AUTOSAR XML (schema 4-3-0)
package /test_pkg/test_swc
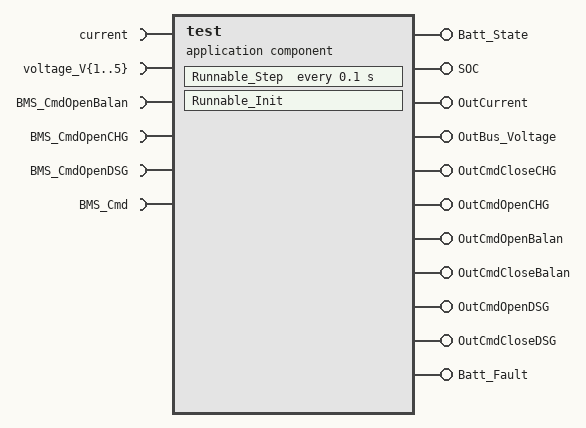
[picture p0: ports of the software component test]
  application sw component type test
    10 x require port:
      current: nonqueued-receiver-com-spec{data-element=current, init-value=0}, required-interface=current
      voltage_V{1..5}: nonqueued-receiver-com-spec{data-element=voltage_V{1..5}, init-value=0}, required-interface=voltage_V{1..5}
      BMS_CmdOpenBalan: nonqueued-receiver-com-spec{data-element=BMS_CmdOpenBalan, init-value=0}, required-interface=BMS_CmdOpenBalan
      BMS_CmdOpenCHG: nonqueued-receiver-com-spec{data-element=BMS_CmdOpenCHG, init-value=0}, required-interface=BMS_CmdOpenCHG
      BMS_CmdOpenDSG: nonqueued-receiver-com-spec{data-element=BMS_CmdOpenDSG, init-value=0}, required-interface=BMS_CmdOpenDSG
      BMS_Cmd: nonqueued-receiver-com-spec{data-element=BMS_Cmd, init-value=0}, required-interface=BMS_Cmd
    11 x provide port:
      Batt_State: nonqueued-sender-com-spec{data-element=Batt_State, init-value=0}, provided-interface=Batt_State
      SOC: nonqueued-sender-com-spec{data-element=SOC, init-value=0}, provided-interface=SOC
      OutCurrent: nonqueued-sender-com-spec{data-element=OutCurrent, init-value=0}, provided-interface=OutCurrent
      OutBus_Voltage: nonqueued-sender-com-spec{data-element=OutBus_Voltage, init-value=0}, provided-interface=OutBus_Voltage
      OutCmdCloseCHG: nonqueued-sender-com-spec{data-element=OutCmdCloseCHG, init-value=0}, provided-interface=OutCmdCloseCHG
      OutCmdOpenCHG: nonqueued-sender-com-spec{data-element=OutCmdOpenCHG, init-value=0}, provided-interface=OutCmdOpenCHG
      OutCmdOpenBalan: nonqueued-sender-com-spec{data-element=OutCmdOpenBalan, init-value=0}, provided-interface=OutCmdOpenBalan
      OutCmdCloseBalan: nonqueued-sender-com-spec{data-element=OutCmdCloseBalan, init-value=0}, provided-interface=OutCmdCloseBalan
      OutCmdOpenDSG: nonqueued-sender-com-spec{data-element=OutCmdOpenDSG, init-value=0}, provided-interface=OutCmdOpenDSG
      OutCmdCloseDSG: nonqueued-sender-com-spec{data-element=OutCmdCloseDSG, init-value=0}, provided-interface=OutCmdCloseDSG
      Batt_Fault: nonqueued-sender-com-spec{data-element=Batt_Fault, init-value=0}, provided-interface=Batt_Fault
    behavior test: handle-termination-and-restart=NO-SUPPORT
      timing event Event_Runnable_Step: start-on-event=Runnable_Step, period=0.1
      runnable Runnable_Init
      runnable Runnable_Step
        data-read-access:
          10 x access:
            IN_BMS_Cmd_BMS_Cmd: accessed-variable=BMS_Cmd.BMS_Cmd
            IN_BMS_CmdOpenBalan_BMS_CmdOpenBalan: accessed-variable=BMS_CmdOpenBalan.BMS_CmdOpenBalan
            IN_BMS_CmdOpenCHG_BMS_CmdOpenCHG: accessed-variable=BMS_CmdOpenCHG.BMS_CmdOpenCHG
            IN_BMS_CmdOpenDSG_BMS_CmdOpenDSG: accessed-variable=BMS_CmdOpenDSG.BMS_CmdOpenDSG
            IN_current_current: accessed-variable=current.current
            IN_voltage_V{1..5}_voltage_V{1..5}: accessed-variable=voltage_V{1..5}.voltage_V{1..5}
        data-write-access:
          11 x access:
            OUT_Batt_State_Batt_State: accessed-variable=Batt_State.Batt_State
            OUT_SOC_SOC: accessed-variable=SOC.SOC
            OUT_OutCurrent_OutCurrent: accessed-variable=OutCurrent.OutCurrent
            OUT_OutBus_Voltage_OutBus_Voltage: accessed-variable=OutBus_Voltage.OutBus_Voltage
            OUT_OutCmdCloseCHG_OutCmdCloseCHG: accessed-variable=OutCmdCloseCHG.OutCmdCloseCHG
            OUT_OutCmdOpenCHG_OutCmdOpenCHG: accessed-variable=OutCmdOpenCHG.OutCmdOpenCHG
            OUT_OutCmdOpenBalan_OutCmdOpenBalan: accessed-variable=OutCmdOpenBalan.OutCmdOpenBalan
            OUT_OutCmdCloseBalan_OutCmdCloseBalan: accessed-variable=OutCmdCloseBalan.OutCmdCloseBalan
            OUT_OutCmdOpenDSG_OutCmdOpenDSG: accessed-variable=OutCmdOpenDSG.OutCmdOpenDSG
            OUT_OutCmdCloseDSG_OutCmdCloseDSG: accessed-variable=OutCmdCloseDSG.OutCmdCloseDSG
            OUT_Batt_Fault_Batt_Fault: accessed-variable=Batt_Fault.Batt_Fault
